# ADC_2 register map
Vendor: Texas Instruments
Peripheral module from a debugger description file (folder msp430).
Registers are 16-bit, read-write, reset 0x0 unless marked. A register's access mark holds for its fields unless they carry their own. Offsets are as the file gives them; lines under a group give offsets from that group; [hi:lo] are bit positions; {n}, {i} and the like mark numbered series; 'fields as' and 'values as' point back to an identical list; <NAME> marks a mode.

## ADC
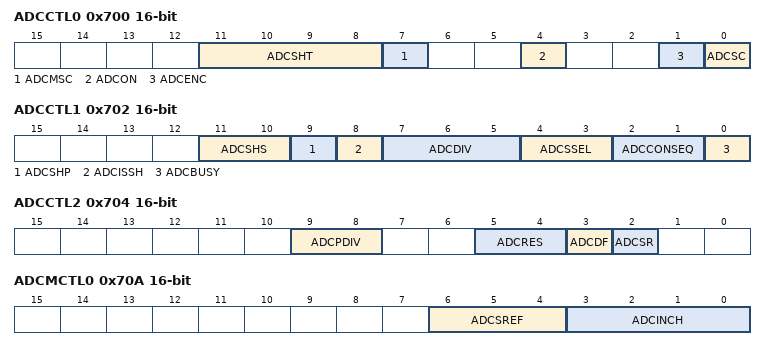
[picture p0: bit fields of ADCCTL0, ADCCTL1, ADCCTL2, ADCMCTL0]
0x700 ADCCTL0 — ADC Control 0
  [11:8] ADCSHT — ADC Sample Hold Select Bit: 0
    {v}=ADC Sample Hold Select {v} (v=0..15)
  [7] ADCMSC — ADC Multiple SampleConversion
  [4] ADCON — ADC On/enable
  [1] ADCENC — ADC Enable Conversion
  [0] ADCSC — ADC Start Conversion
0x702 ADCCTL1 — ADC Control 1
  [11:10] ADCSHS — ADC Sample/Hold Source 0
    {v}=ADC Sample/Hold Source: {v} (v=0..3)
  [9] ADCSHP — ADC Sample/Hold Pulse Mode
  [8] ADCISSH — ADC Invert Sample Hold Signal
  [7:5] ADCDIV — ADC Clock Divider Select 0
    {v}=ADC Clock Divider Select: {v} (v=0..7)
  [4:3] ADCSSEL — ADC Clock Source Select 0
    {v}=ADC Clock Source Select: {v} (v=0..3)
  [2:1] ADCCONSEQ — ADC Conversion Sequence Select 0
    {v}=ADC Conversion Sequence Select: {v} (v=0..3)
  [0] ADCBUSY
0x704 ADCCTL2 — ADC Control 2
  [9:8] ADCPDIV — ADC predivider Bit: 0
    0=ADC predivider /1; 1=ADC predivider /2; 2=ADC predivider /64; 3=ADC predivider reserved
  [5:4] ADCRES — ADC Resolution
    0=8 bit; 1=10 bit
  [3] ADCDF — ADC Data Format
  [2] ADCSR — ADC Sampling Rate
0x706 ADCLO access not given reset not defined — ADC Window Comparator High Threshold
0x708 ADCHI access not given reset not defined — ADC Window Comparator High Threshold
0x70A ADCMCTL0 — ADC Memory Control 0
  [6:4] ADCSREF — ADC Select Reference Bit 0
    {v}=ADC Select Reference {v} (v=0..7)
  [3:0] ADCINCH — ADC Input Channel Select Bit 0
    {v}=ADC Input Channel {v} (v=0..15)
0x712 ADCMEM0 access not given reset not defined — ADC Conversion Memory 0
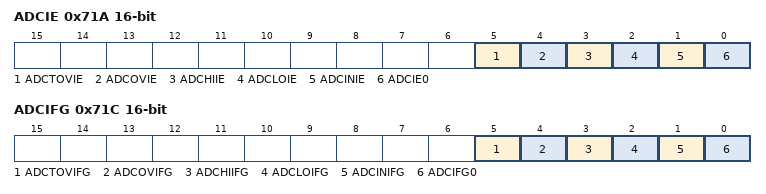
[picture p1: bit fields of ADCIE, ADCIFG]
0x71A ADCIE — ADC Interrupt Enable
  [5] ADCTOVIE — ADC conversion-time-overflow Interrupt enable
  [4] ADCOVIE — ADC ADCMEM overflow Interrupt enable
  [3] ADCHIIE — ADC Interrupt enable for upper threshold of the Window comparator
  [2] ADCLOIE — ADC Interrupt enable for lower threshold of the Window comparator
  [1] ADCINIE — ADC Interrupt enable for the inside of window of the Window comparator
  [0] ADCIE0 — ADC Interrupt enable
0x71C ADCIFG — ADC Interrupt Flag
  [5] ADCTOVIFG — ADC conversion-time-overflow Interrupt Flag
  [4] ADCOVIFG — ADC ADCMEM overflow Interrupt Flag
  [3] ADCHIIFG — ADC Interrupt Flag for upper threshold of the Window comparator
  [2] ADCLOIFG — ADC Interrupt Flag for lower threshold of the Window comparator
  [1] ADCINIFG — ADC Interrupt Flag for the inside of window of the Window comparator
  [0] ADCIFG0 — ADC Interrupt Flag
0x71E ADCIV access not given reset not defined — ADC Interrupt Vector Word
